# CH585SFR register map
Vendor: WCH Ltd.; Series: CH58x; File version: 1.0
CPU: RISC-V r0p0, little endian, no MPU, no FPU, 2 interrupt priority bits
Registers are 8-bit, Read or Write, reset 0x0 unless marked. A register's access mark holds for its fields unless they carry their own. Offsets are from the block's base; [hi:lo] are bit positions.

## USBHS — USB register
Base 0x40009000
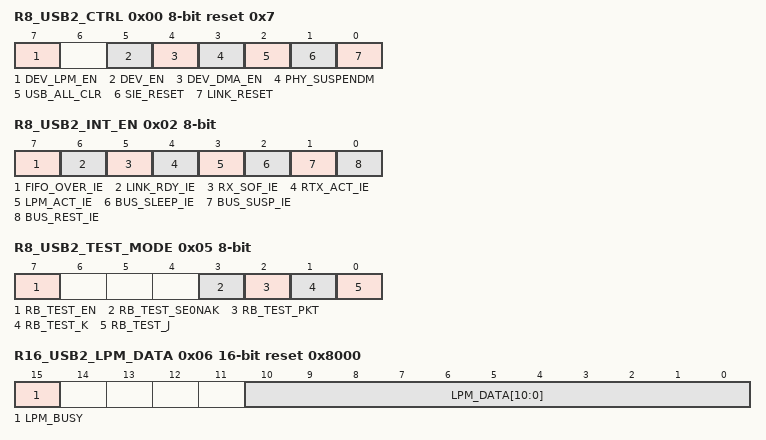
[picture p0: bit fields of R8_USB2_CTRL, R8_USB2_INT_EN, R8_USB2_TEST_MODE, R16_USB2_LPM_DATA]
0x00 R8_USB2_CTRL Read and Write reset 0x7 — RW, USBHS control register
  [7] DEV_LPM_EN — LPM Enable
  [5] DEV_EN — USB device enablement
  [4] DEV_DMA_EN — DMA transfer enable
  [3] PHY_SUSPENDM — USB PHY suspended
  [2] USB_ALL_CLR — Clear all interrupt flags
  [1] SIE_RESET — USB protocol processor reset, including endpoint related registers, highly effective
  [0] LINK_RESET — LINK layer reset, highly effective
0x01 R8_USB2_BASE_MODE Read and Write — RW, USBHS control register
  [1:0] EXP_SPD[1:0] — Expected speed mode of the device
0x02 R8_USB2_INT_EN Read and Write — RW, USBHS interrupt enable register
  [7] FIFO_OVER_IE — FIFO overflow interrupt
  [6] LINK_RDY_IE — USB connection interruption enabled
  [5] RX_SOF_IE — Receive SOF packet interrupt enable
  [4] RTX_ACT_IE — USB Transfer End Interrupt Enable
  [3] LPM_ACT_IE — LPM transmission end interrupt enable
  [2] BUS_SLEEP_IE — USB bus sleep interrupt enable
  [1] BUS_SUSP_IE — USB bus pause interrupt enable
  [0] BUS_REST_IE — USB bus reset interrupt enable
0x03 R8_USB2_DEV_AD Read and Write — RW, USBHS device address register
  [6:0] RB_MASK_USB_ADDR[6:0] — USB device address
0x04 R8_USB2_WAKE_CTRL RW1Z — RW1Z, USBHS remote wake-up register
  [0] RB_RMT_WAKE — Remote wake-up, hardware auto reset
0x05 R8_USB2_TEST_MODE Read and Write — RW, USBHS test mode register
  [7] RB_TEST_EN — Enable Test Mode
  [3] RB_TEST_SE0NAK — Test mode, output SE0
  [2] RB_TEST_PKT — Test mode, output a package
  [1] RB_TEST_K — Test mode, output K
  [0] RB_TEST_J — Test mode, output J
0x06 R16_USB2_LPM_DATA 16-bit Read and Write reset 0x8000 — RW, USBHS power management register
  [15] LPM_BUSY — Power management busy
  [10:0] LPM_DATA[10:0] — Power management data
0x08 R8_USB2_INT_FG RW1Z — RW1Z, USBHS interrupt flag register
  [7] RB_UIF_FIFO_OV_HS — FIFO overflow interrupt flag bit, write 1 to reset to zero
  [6] RB_UIF_LINK_RDY — USB connection interruption flag bit, write 1 to reset to zero
  [5] RB_UIF_RX_SOF — Receive SOF packet interrupt flag, write 1 to reset to zero
  [4] RB_UIF_RTX_ACT — USB transfer end interrupt flag bit, cleared by RB-UMS_SHMOD bit
  [3] RB_UIF_LPM_ACT — LPM transmission end interrupt flag, write 1 to reset to zero
  [3] RB_UIF_LPM_ACT — LPM transmission end interrupt flag, write 1 to reset to zero
  [2] RB_UIF_BUS_SLEEP — USB bus sleep interrupt flag, write 1 to reset to zero
  [1] RB_UIF_SUSPEND_HS — USB bus hangs interrupt flag, write 1 to reset to zero
  [0] RB_UIF_BUS_RST — USB bus reset interrupt flag bit, write 1 to reset to zero
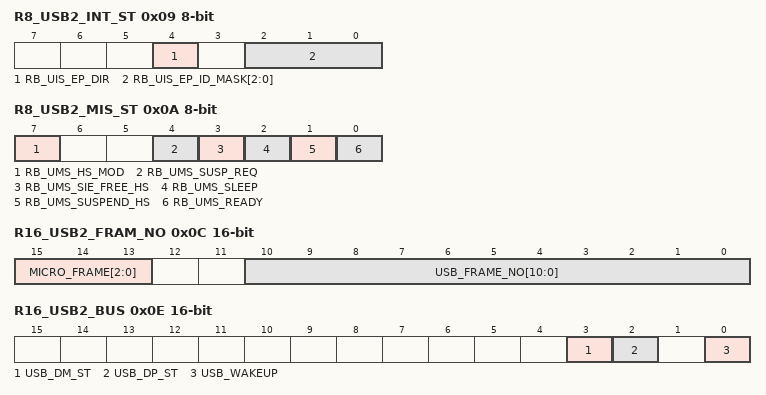
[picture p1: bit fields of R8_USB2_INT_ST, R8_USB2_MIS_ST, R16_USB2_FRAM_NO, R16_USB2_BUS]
0x09 R8_USB2_INT_ST ro — RO, USBHS Interrupt Status Register
  [4] RB_UIS_EP_DIR — Endpoint data transmission direction
  [2:0] RB_UIS_EP_ID_MASK[2:0] — Endpoint number where data transmission occurs
0x0A R8_USB2_MIS_ST ro — RO, USBHS Miscellaneous Status Register
  [7] RB_UMS_HS_MOD — Is the host high-speed
  [4] RB_UMS_SUSP_REQ — USB suspend request
  [3] RB_UMS_SIE_FREE_HS — USB idle state
  [2] RB_UMS_SLEEP — USB sleep state
  [1] RB_UMS_SUSPEND_HS — USB suspended status
  [0] RB_UMS_READY — USB connection status
0x0C R16_USB2_FRAM_NO 16-bit ro — RO, USBHS frame register
  [15:13] MICRO_FRAME[2:0] — Received microframe number
  [10:0] USB_FRAME_NO[10:0] — Received frame number
0x0E R16_USB2_BUS 16-bit ro — RO, USBHS bus status memory
  [3] USB_DM_ST — UDM status
  [2] USB_DP_ST — UDP status
  [0] USB_WAKEUP — USB wake-up (highly effective)
0x10 R16_UEP_TX_EN 16-bit Read and Write — RW, USBHS endpoint sends enable register
  [15:0] UEP_TX_EN[15:0] — 0~15 endpoints send enable
0x12 R16_UEP_RX_EN 16-bit Read and Write — RW, USBHS endpoint receive enable register
  [15:0] UEP_RX_EN[15:0] — 0~15 endpoints receive enable
0x14 R16_UEP_T_TOG_AUTO 16-bit Read and Write — RW, USBHS endpoint receives automatic flip enable register
  [7:0] UEP_T_TOG_AUTO[7:0] — 0~7 endpoint synchronization trigger bit automatic flip enable
0x16 R16_UEP_R_TOG_AUTO 16-bit Read and Write — RW, USBHS endpoint receives automatic flip enable register
  [7:0] UEP_R_TOG_AUTO[7:0] — 0~7 endpoint synchronization trigger bit automatic flip enable
0x18 R8_UEP_T_BURST Read and Write — RW, 0~7 endpoints burst send enable
  [7:0] UEP_T_BURST_EN[7:0] — 0~7 endpoints burst send enable
0x19 R8_UEP_T_BURST_MODE Read and Write — RW, USBHS Endpoint Send Mode Register
  [7:0] UEP_T_BURST_EN[7:0] — 0~7 endpoints burst send enable
0x1A R8_UEP_R_BURST Read and Write — RW, 0~7 endpoints burst receive enable
  [7:0] UEP_R_BURST_EN[7:0] — 0~7 endpoints burst receive enable
0x1B R8_UEP_R_RES_MODE Read and Write — RW, USBHS Endpoint Receive Mode Register
  [7:0] UEP_R_RES_MODE[7:0] — 0~7 endpoints burst receive enable
0x1C R32_UEP_AF_MODE 32-bit Read and Write — RW, USBHS Endpoint Reuse Register
  [7:1] UEP_T_AF[6:0] — 1-7 endpoint reuse enabled
0x20 R32_UEP0_DMA 32-bit Read and Write reset not defined — RW, Starting address register of endpoint 0 buffer
  [7:1] UEP_T_AF[6:0] — 1-7 endpoint reuse enabled
0x20 R32_UEPn_RX_DMA(n=1~7) 32-bit Read and Write reset not defined — RW, Endpoint n receives the starting address register of the buffer(n=1~7)
  [16:0] UEPn_RX_DMA[16:0] — The starting address of the receiving buffer for endpoint n. The address must be aligned with 4 bytes
0x40 R32_UEPn_TX_DMA(n=1~7) 32-bit Read and Write reset not defined — RW, Endpoint n sends the starting address register of the buffer(n=1~7)
  [16:0] R32_UEPn_TX_DMA[16:0] — The starting address of the sending buffer for endpoint n. The address must be aligned with 4 bytes
0x5C R32_UEPn_MAX_LEN(n=1~7) 32-bit Read and Write reset not defined — RW, Endpoint n maximum length packet register(n=1~7)
  [6:0] UEPn_MAX_LEN[6:0]
0x7C R16_UEP0_RX_LEN 16-bit Read and Write reset not defined — RW, Endpoint 0 receives length register
  [15:0] UEPn_MAX_LEN[6:0]
0x80 R16_UEPn_RX_LEN(n=1~7) 16-bit Read and Write reset not defined — RW, Endpoint n single reception length register(n=1~7)
  [15:0] UEPn_RX_LEN[15:0] — Endpoint n receives data length in a single session(n=1~7)
0x9C R16_UEP0_T_LEN 16-bit Read and Write reset not defined — RW, Endpoint 0 sends length register
  [6:0] UEP0_T_LEN[6:0] — Endpoint 0 sends data length
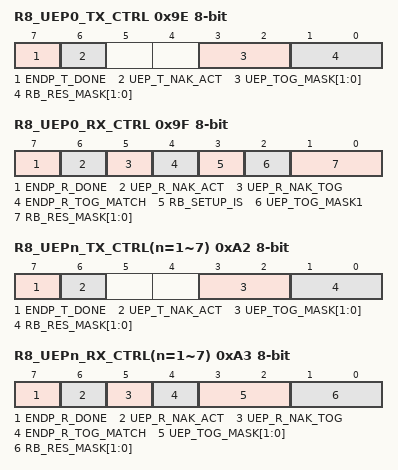
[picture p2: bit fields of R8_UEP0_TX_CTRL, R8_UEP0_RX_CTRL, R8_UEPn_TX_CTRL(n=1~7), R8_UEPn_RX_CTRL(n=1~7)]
0x9E R8_UEP0_TX_CTRL Read and Write — RW, Endpoint 0 sends control register
  [7] ENDP_T_DONE — Endpoint 0 sends end flag, write 0 to clear
  [6] UEP_T_NAK_ACT — Endpoint 0 sends NAK end flag, write 0 to clear
  [3:2] UEP_TOG_MASK[1:0] — Expected synchronization trigger bit for endpoint 0
  [1:0] RB_RES_MASK[1:0] — Endpoint 0 controls the response sent
0x9F R8_UEP0_RX_CTRL Read and Write — RW, Endpoint 0 receives control register
  [7] ENDP_R_DONE — Endpoint 0 receives end flag, write 0 to clear
  [6] UEP_R_NAK_ACT — Endpoint 0 receives NAK end flag, write 0 to clear
  [5] UEP_R_NAK_TOG — Endpoint 0 returns NAK for received data packet type
  [4] ENDP_R_TOG_MATCH — The received synchronization trigger bit matches the expected synchronization trigger bit
  [3] RB_SETUP_IS — Is the transaction received by endpoint 0 a SETUP transaction
  [2] UEP_TOG_MASK1 — Expected synchronization trigger bit for receiving endpoint 0
  [1:0] RB_RES_MASK[1:0] — Endpoint 0 controls the received response
0xA0 R16_UEPn_T_LEN(n=1~7) 16-bit Read and Write — RW, Endpoint n sends data length(n=1~7)
  [15:0] UEPn_T_LEN[15:0] — Endpoint n sends data length(n=1~7)
0xA2 R8_UEPn_TX_CTRL(n=1~7) Read and Write — RW, Endpoint n sends data length(n=1~7)
  [7] ENDP_T_DONE — Endpoint n sends an end flag, write 0 to clear(n=1~7)
  [6] UEP_T_NAK_ACT — Endpoint n sends NAK end flag, write 0 to clear(n=1~7)
  [3:2] UEP_TOG_MASK[1:0] — Expected synchronization trigger bit for endpoint n's sending(n=1~7)
  [1:0] RB_RES_MASK[1:0] — Endpoint n controls the response sent(n=1~7)
0xA3 R8_UEPn_RX_CTRL(n=1~7) Read and Write — RW, Endpoint n receives control registers(n=1~7)
  [7] ENDP_R_DONE — Endpoint n receives the end flag, write 0 to clear(n=1~7)
  [6] UEP_R_NAK_ACT — Endpoint n receives NAK end flag, writes 0 to clear(n=1~7)
  [5] UEP_R_NAK_TOG — Endpoint n receives the return NAK and packet type(n=1~7)
  [4] ENDP_R_TOG_MATCH — The synchronization trigger bit received by endpoint n matches the expected synchronization trigger bit(n=1~7)
  [3:2] UEP_TOG_MASK[1:0] — Expected synchronization trigger bit for receiving endpoint n(n=1~7)
  [1:0] RB_RES_MASK[1:0] — Endpoint n controls the received response(n=1~7)
0xBC R16_UEP_T_ISO 16-bit Read and Write — RW, USBHS endpoint sends synchronization mode enable register
  [7:1] UEP_T_ISO[6：0] — Upload endpoint (IN) synchronization mode enabled
0xBE R16_UEP_R_ISO 16-bit Read and Write — RW, USBHS endpoint receiving synchronization mode enable register
  [7:1] UEP_R_ISO[6：0] — Enable the synchronization mode of the downstream endpoint (OUT)
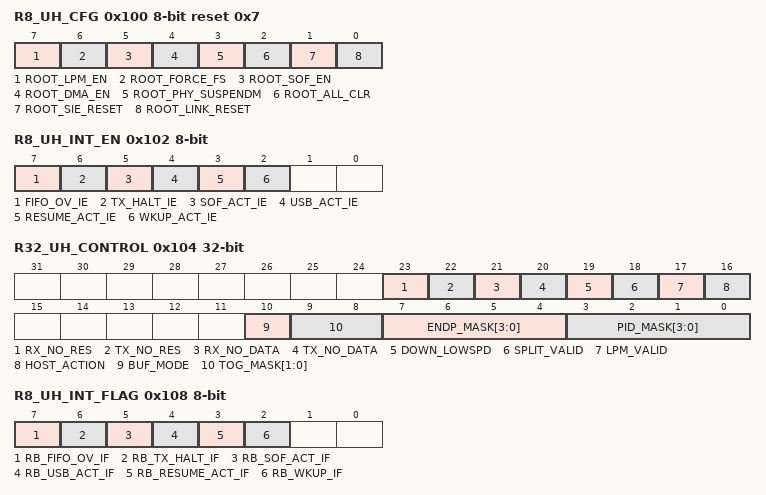
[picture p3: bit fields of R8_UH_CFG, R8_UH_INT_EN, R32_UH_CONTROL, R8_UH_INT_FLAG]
0x100 R8_UH_CFG Read and Write reset 0x7 — RW, USBHS Host Configuration Register
  [7] ROOT_LPM_EN — Enable LPM
  [6] ROOT_FORCE_FS — Force full speed FS
  [5] ROOT_SOF_EN — Enable SOF packet transmission
  [4] ROOT_DMA_EN — Enable DMA transmission
  [3] ROOT_PHY_SUSPENDM — PHY hangs, turn off the UTMI clock of the controller
  [2] ROOT_ALL_CLR — Clear interrupt flag and FIFO, software zeroing is required
  [1] ROOT_SIE_RESET — USB protocol processor reset, software reset required
  [0] ROOT_LINK_RESET — USB connection control module reset
0x102 R8_UH_INT_EN Read and Write — RW, USBHS host interrupt enable register
  [7] FIFO_OV_IE — FIFO overflow interrupt enable
  [6] TX_HALT_IE — Enable sending pause interrupt
  [5] SOF_ACT_IE — Enable SOF packet sending interrupt
  [4] USB_ACT_IE — USB end or transfer completion interrupt enable
  [3] RESUME_ACT_IE — Bus recovery interrupt enable
  [2] WKUP_ACT_IE — Wake up interrupt enable
0x103 R8_UH_DEV_ADDR Read and Write — RW, USBHS host device address register
  [7:0] DEV_ADDR[7:0] — Device Address
0x104 R32_UH_CONTROL 32-bit Read and Write reset not defined — RW, USBHS Host Control Register
  [23] RX_NO_RES — IN-DATA no response, used for synchronous transmission or high-speed SPLIT packets
  [22] TX_NO_RES — OUT/SETUP - DATA does not expect a response, used for synchronous transmission or high-speed SPLIT packets
  [21] RX_NO_DATA — Expected data packet after IN token packet, used for high-speed SPLIT packet
  [20] TX_NO_DATA — There is no data packet after the OUT/SETUP token packet, used for high-speed SPLIT packets
  [19] DOWN_LOWSPD — When the port is operating at full speed and needs to send low-speed packets (PRE), this bit must be enabled
  [18] SPLIT_VALID — Sending SPLIT package is valid
  [17] LPM_VALID — Sending LPM package is valid
  [16] HOST_ACTION — HOST enables transaction execution, and this bit is automatically reset to zero after the transaction is completed
  [10] BUF_MODE — Data cache control bit
  [9:8] TOG_MASK[1:0] — Sent data PID
  [7:4] ENDP_MASK[3:0] — Transaction token package endpoint number
  [3:0] PID_MASK[3:0] — Transaction token package PID
0x108 R8_UH_INT_FLAG RW1Z — RW1Z, USBHS host interrupt flag register
  [7] RB_FIFO_OV_IF — FIFO overflow interrupt flag
  [6] RB_TX_HALT_IF — Send abort interrupt flag
  [5] RB_SOF_ACT_IF — SOF packet sending completion interrupt flag, write 1 to reset to zero
  [4] RB_USB_ACT_IF — USB transaction transfer completion interrupt flag, write 1 to reset to zero
  [3] RB_RESUME_ACT_IF — Bus recovery interrupt flag, write 1 to reset to zero
  [2] RB_WKUP_IF — Wake up interrupt flag, write 1 to reset to zero
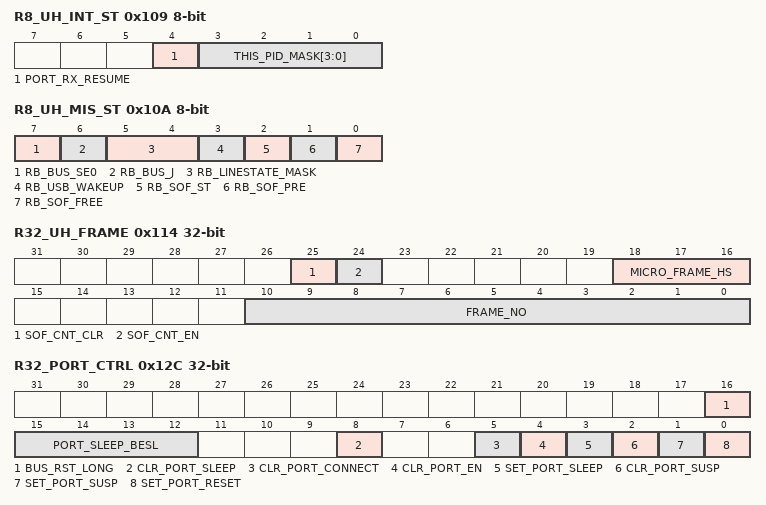
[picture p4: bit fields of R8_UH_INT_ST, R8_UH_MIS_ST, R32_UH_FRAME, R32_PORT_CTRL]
0x109 R8_UH_INT_ST Read and Write reset not defined — RW, USBHS host interrupt status register
  [4] PORT_RX_RESUME — This bit is 1, indicating that the port has received a wake-up signal
  [3:0] THIS_PID_MASK[3:0] — Received PID.
0x10A R8_UH_MIS_ST Read and Write reset not defined — RW, USBHS host miscellaneous status register
  [7] RB_BUS_SE0 — SEO on USB bus
  [6] RB_BUS_J — J on the USB bus
  [5:4] RB_LINESTATE_MASK — USB bus status
  [3] RB_USB_WAKEUP — USB bus wake-up
  [2] RB_SOF_ST — USB bus SOF status
  [1] RB_SOF_PRE — The USB bus SOF packet indicates a status of
  [0] RB_SOF_FREE — Port enabled status
0x10C R32_UH_LPM 32-bit Read and Write reset not defined — RW, USBHS Host Power Management Data Register
  [10:0] LPM_DATA — Power management data
0x110 R32_UH_SPLIT 32-bit Read and Write reset not defined — RW, USBHS Host SPLIT Register
  [18:0] SPLIT_DATA
0x114 R32_UH_FRAME 32-bit Read and Write — RW, USBHS Host Frame Register
  [25] SOF_CNT_CLR — SOF count reset to zero
  [24] SOF_CNT_EN — SOF Count Enable
  [18:16] MICRO_FRAME_HS — Micro frame number
  [10:0] FRAME_NO — frame number
0x118 R32_UH_TX_LEN 32-bit Read and Write reset not defined — RW, USBHS host sends length register
  [10:0] TX_LEN — Sending data length
0x11C R32_UH_RX_LEN 32-bit Read and Write reset not defined — RW, USBHS host receives length register
  [10:0] RX_LEN — Received data length
0x120 R32_UH_RX_MAX_LEN 32-bit Read and Write reset not defined — RW, USBHS host receives maximum length register
  [10:0] UH_RX_MAX_LEN — Received data max length
0x124 R32_UH_RX_DMA 32-bit Read and Write reset not defined — RW, DMA receiving address register
  [16:0] R32_UH_RX_DMA — Receiving Address
0x128 R32_UH_TX_DMA 32-bit Read and Write reset not defined — RW, DMA sending address register
  [16:0] R16_UH_TX_DMA_HS — Sending Address
0x12C R32_PORT_CTRL 32-bit ro reset not defined — WO, USBHS host port control register
  [16] BUS_RST_LONG — Bus reset time selection
  [15:12] PORT_SLEEP_BESL — Wake up time control
  [8] CLR_PORT_SLEEP — PORT exits SLEEP state (LPM)
  [5] CLR_PORT_CONNECT — Put the port into port state
  [4] CLR_PORT_EN — PORT exits the enabled state and enters the disabled state
  [3] SET_PORT_SLEEP — PORT enters SLEEP state (LPM)
  [2] CLR_PORT_SUSP — PORT exits suspended state
  [1] SET_PORT_SUSP — PORT enters suspended state
  [0] SET_PORT_RESET — Port sending reset
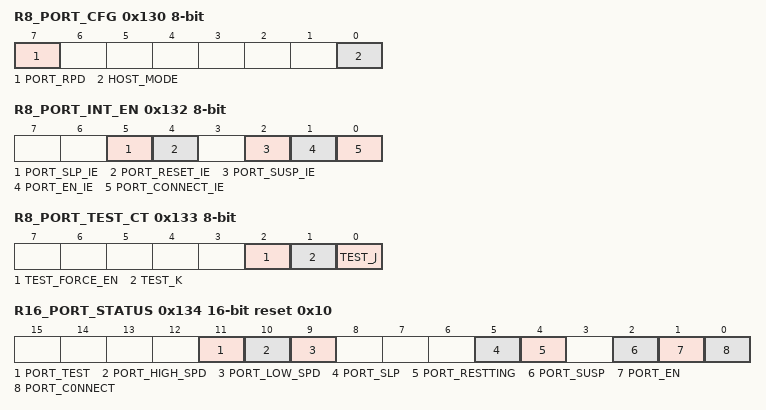
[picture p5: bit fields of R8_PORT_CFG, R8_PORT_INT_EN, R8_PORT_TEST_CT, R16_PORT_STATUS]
0x130 R8_PORT_CFG ro — RO, USBHS host port configuration register
  [7] PORT_RPD — Enable 15K resistor pull-down in host mode
  [0] HOST_MODE — USB port mode selection
0x132 R8_PORT_INT_EN ro — RO, USBHS host port configuration register
  [5] PORT_SLP_IE — Port sleep state change interrupt enable
  [4] PORT_RESET_IE — Port reset status change interrupt enable
  [2] PORT_SUSP_IE — Port pause status change interrupt enable
  [1] PORT_EN_IE — Port enable status change interrupt enable
  [0] PORT_CONNECT_IE — Port connection status change interrupt enable
0x133 R8_PORT_TEST_CT Read and Write — RW, USBHS host port test mode register
  [2] TEST_FORCE_EN — Enable Test Mode
  [1] TEST_K — Test output K
  [0] TEST_J — Test output J
0x134 R16_PORT_STATUS 16-bit ro reset 0x10 — RO, USBHS Host Port Status Register
  [11] PORT_TEST — Is the port in test mode
  [10] PORT_HIGH_SPD — Is the port connection speed high
  [9] PORT_LOW_SPD — Is the port connection speed low
  [5] PORT_SLP — Port sleep
  [4] PORT_RESTTING — Port reset status
  [2] PORT_SUSP — Port paused state
  [1] PORT_EN — Port Enable
  [0] PORT_C0NNECT — Port connection status
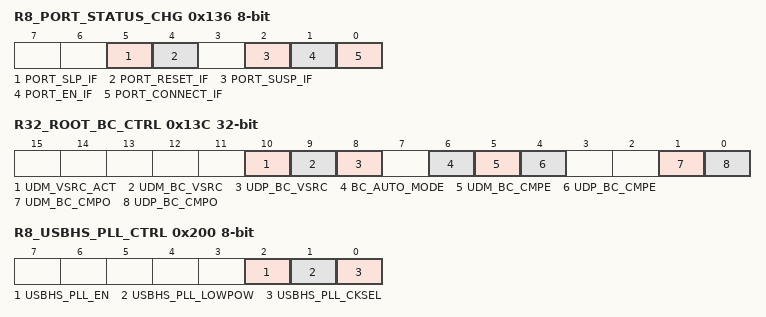
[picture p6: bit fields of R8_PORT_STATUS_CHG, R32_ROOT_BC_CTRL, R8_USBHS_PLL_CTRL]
0x136 R8_PORT_STATUS_CHG RW1Z — RW1Z, USBHS Host Port Status Register
  [5] PORT_SLP_IF — Port sleep status changes, write 1 to reset to zero
  [4] PORT_RESET_IF — Port reset status changes, write 1 to reset to zero
  [2] PORT_SUSP_IF — Port pause status changes, write 1 to reset to zero
  [1] PORT_EN_IF — Port enable status changes, write 1 to reset to zero
  [0] PORT_CONNECT_IF — Port connection status changes, write 1 to reset to zero
0x13C R32_ROOT_BC_CTRL 32-bit Read and Write — RW, USBHS host BC charging control register
  [10] UDM_VSRC_ACT — In automatic mode, this bit represents the UDM output VBC_SRC, otherwise it is controlled by UDM-BC_CMPE
  [9] UDM_BC_VSRC — UDM pin BC protocol source voltage enabled
  [8] UDP_BC_VSRC — UDP pin BC protocol source voltage enable
  [6] BC_AUTO_MODE — Automatic mode enabled
  [5] UDM_BC_CMPE — UDM pin BC protocol comparator enabled
  [4] UDP_BC_CMPE — UDP pin BC protocol comparator enabled
  [1] UDM_BC_CMPO — UDM pin BC protocol comparator status
  [0] UDP_BC_CMPO — UDP pin BC protocol comparator status
0x200 R8_USBHS_PLL_CTRL Read and Write — RW, USBHS PLL Clock Control Register
  [2] USBHS_PLL_EN — USBHS PLL Enable
  [1] USBHS_PLL_LOWPOW — USBHS PLL low-power mode (can only be enabled when USB20 application is at fixed low full speed, cannot be enabled when not at fixed low full speed)
  [0] USBHS_PLL_CKSEL — Selection of internal reference clock source for USBHS
